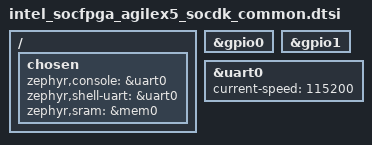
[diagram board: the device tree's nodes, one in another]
/*
 * SPDX-FileCopyrightText: Copyright (c) 2026, Altera Corporation.
 *
 * SPDX-License-Identifier: Apache-2.0
 */

#include <intel/intel_socfpga_agilex5.dtsi>

/ {
	chosen {
		zephyr,console = &uart0;
		zephyr,shell-uart = &uart0;
		zephyr,sram = &mem0;
	};
};

&gpio0 {
	status = "okay";
};

&gpio1 {
	status = "okay";
};

&uart0 {
	status = "okay";
	current-speed = <115200>;
};
